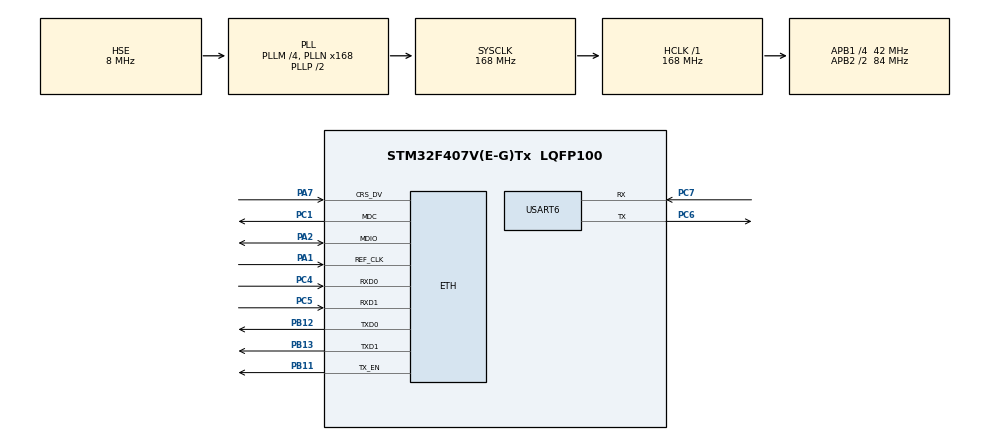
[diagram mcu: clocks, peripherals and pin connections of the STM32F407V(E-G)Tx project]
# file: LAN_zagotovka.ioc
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ETH.MediaInterface=ETH_MEDIA_INTERFACE_RMII
LWIP.API_LIB_DEBUG=LWIP_DBG_ON
LWIP.API_MSG_DEBUG=LWIP_DBG_ON
LWIP.AUTOIP_DEBUG=LWIP_DBG_ON
LWIP.DHCP6_DEBUG=LWIP_DBG_ON
LWIP.DHCP_DEBUG=LWIP_DBG_ON
LWIP.DNS_DEBUG=LWIP_DBG_ON
LWIP.ETHARP_DEBUG=LWIP_DBG_ON
LWIP.GATEWAY_ADDRESS=192.168.018.001
LWIP.HTTPD_DEBUG=LWIP_DBG_ON
LWIP.HTTPD_DEBUG_TIMING=LWIP_DBG_ON
LWIP.ICMP_DEBUG=LWIP_DBG_ON
LWIP.IGMP_DEBUG=LWIP_DBG_ON
LWIP.INET_DEBUG=LWIP_DBG_ON
LWIP.IP6_DEBUG=LWIP_DBG_ON
LWIP.IP_ADDRESS=192.168.018.111
LWIP.IP_DEBUG=LWIP_DBG_ON
LWIP.IP_REASS_DEBUG=LWIP_DBG_ON
LWIP.LWIP_DHCP=1
LWIP.LWIP_HTTPD=1
LWIP.LWIP_HTTPD_CGI=1
LWIP.LWIP_HTTPD_DYNAMIC_HEADERS=1
LWIP.LWIP_HTTPD_MAX_REQUEST_URI_LEN=1000
LWIP.LWIP_HTTPD_MAX_REQ_LENGTH=1500
LWIP.LWIP_HTTPD_MAX_TAG_INSERT_LEN=800
LWIP.LWIP_HTTPD_SSI=1
LWIP.LWIP_HTTPD_SSI_INCLUDE_TAG=0
LWIP.LWIP_HTTPD_SSI_MULTIPART=1
LWIP.LWIP_HTTPD_SUPPORT_POST=1
LWIP.LWIP_NETIF_LINK_CALLBACK=1
LWIP.LWIP_TESTMODE=1
LWIP.MDNS_DEBUG=LWIP_DBG_ON
LWIP.MEMP_DEBUG=LWIP_DBG_ON
LWIP.MEMP_NUM_PBUF=16
LWIP.MEMP_NUM_SYS_TIMEOUT=5
LWIP.MEMP_NUM_TCP_PCB=10
LWIP.MEMP_NUM_TCP_SEG=16
LWIP.MEMP_NUM_UDP_PCB=10
LWIP.MEM_DEBUG=LWIP_DBG_ON
LWIP.NETIF_DEBUG=LWIP_DBG_ON
LWIP.NETMASK_ADDRESS=255.255.255.000
LWIP.PBUF_DEBUG=LWIP_DBG_ON
LWIP.PBUF_POOL_SIZE=16
LWIP.PPP_DEBUG=LWIP_DBG_ON
LWIP.RAW_DEBUG=LWIP_DBG_ON
LWIP.SLIP_DEBUG=LWIP_DBG_ON
LWIP.SMTP_DEBUG=LWIP_DBG_ON
LWIP.SNMP_DEBUG=LWIP_DBG_ON
LWIP.SNMP_MIB_DEBUG=LWIP_DBG_ON
LWIP.SNTP_DEBUG=LWIP_DBG_ON
LWIP.SOCKETS_DEBUG=LWIP_DBG_ON
LWIP.SYS_DEBUG=LWIP_DBG_ON
LWIP.TCPIP_DEBUG=LWIP_DBG_ON
LWIP.TCP_CWND_DEBUG=LWIP_DBG_ON
LWIP.TCP_DEBUG=LWIP_DBG_ON
LWIP.TCP_FR_DEBUG=LWIP_DBG_ON
LWIP.TCP_INPUT_DEBUG=LWIP_DBG_ON
LWIP.TCP_OUTPUT_DEBUG=LWIP_DBG_ON
LWIP.TCP_QLEN_DEBUG=LWIP_DBG_ON
LWIP.TCP_RST_DEBUG=LWIP_DBG_ON
LWIP.TCP_RTO_DEBUG=LWIP_DBG_ON
LWIP.TCP_WND_DEBUG=LWIP_DBG_ON
LWIP.TFTP_DEBUG=LWIP_DBG_ON
LWIP.TIMERS_DEBUG=LWIP_DBG_ON
LWIP.UDP_DEBUG=LWIP_DBG_ON
LWIP.Version=v2.1.2_Cube
Mcu.Family=STM32F4
Mcu.Name=STM32F407V(E-G)Tx
Mcu.Package=LQFP100
NVIC.PriorityGroup=NVIC_PRIORITYGROUP_4
NVIC.TIM8_TRG_COM_TIM14_IRQn=true\:15\:0\:false\:false\:true\:false\:true
NVIC.TimeBase=TIM8_TRG_COM_TIM14_IRQn
NVIC.TimeBaseIP=TIM14
PA1.Mode=RMII
PA1.Signal=ETH_REF_CLK
PA13.Mode=Serial_Wire
PA13.Signal=SYS_JTMS-SWDIO
PA14.Mode=Serial_Wire
PA14.Signal=SYS_JTCK-SWCLK
PA2.Mode=RMII
PA2.Signal=ETH_MDIO
PA7.Mode=RMII
PA7.Signal=ETH_CRS_DV
PB11.Mode=RMII
PB11.Signal=ETH_TX_EN
PB12.Mode=RMII
PB12.Signal=ETH_TXD0
PB13.Mode=RMII
PB13.Signal=ETH_TXD1
PC1.Mode=RMII
PC1.Signal=ETH_MDC
PC4.Mode=RMII
PC4.Signal=ETH_RXD0
PC5.Mode=RMII
PC5.Signal=ETH_RXD1
PC6.Mode=Asynchronous
PC6.Signal=USART6_TX
PC7.Mode=Asynchronous
PC7.Signal=USART6_RX
PH0-OSC_IN.Mode=HSE-External-Oscillator
PH0-OSC_IN.Signal=RCC_OSC_IN
PH1-OSC_OUT.Mode=HSE-External-Oscillator
PH1-OSC_OUT.Signal=RCC_OSC_OUT
ProjectManager.HeapSize=0x200
ProjectManager.StackSize=0x400
ProjectManager.TargetToolchain=STM32CubeIDE
RCC.48MHZClocksFreq_Value=84000000
RCC.AHBFreq_Value=168000000
RCC.APB1CLKDivider=RCC_HCLK_DIV4
RCC.APB1Freq_Value=42000000
RCC.APB1TimFreq_Value=84000000
RCC.APB2CLKDivider=RCC_HCLK_DIV2
RCC.APB2Freq_Value=84000000
RCC.APB2TimFreq_Value=168000000
RCC.CortexFreq_Value=168000000
RCC.HCLKFreq_Value=168000000
RCC.HSE_VALUE=8000000
RCC.HSI_VALUE=16000000
RCC.LSE_VALUE=32768
RCC.PLLM=4
RCC.PLLN=168
RCC.PLLSourceVirtual=RCC_PLLSOURCE_HSE
RCC.SYSCLKFreq_VALUE=168000000
RCC.SYSCLKSource=RCC_SYSCLKSOURCE_PLLCLK
RCC.VCOOutputFreq_Value=336000000
USART6.VirtualMode=VM_ASYNC
VP_LWIP_VS_Enabled.Mode=Enabled
VP_SYS_VS_tim14.Mode=TIM14
board=custom

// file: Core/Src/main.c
/* USER CODE BEGIN Header */
/**
  ******************************************************************************
  * @file           : main.c
  * @brief          : Main program body
  ******************************************************************************
  * @attention
  *
  * Copyright (c) 2022 STMicroelectronics.
  * All rights reserved.
  *
  * This software is licensed under terms that can be found in the LICENSE file
  * in the root directory of this software component.
  * If no LICENSE file comes with this software, it is provided AS-IS.
  *
  ******************************************************************************
  */
/* USER CODE END Header */
#include "main.h"
#include "lwip.h"

/* USER CODE BEGIN Includes */
#include <stdio.h>/* для printf */
#include "lwip/apps/httpd.h" // including httpd.h [- HTTPd #1 -]
/* USER CODE END Includes */

UART_HandleTypeDef huart6;

void SystemClock_Config(void);
static void MX_GPIO_Init(void);
static void MX_USART6_UART_Init(void);
/* USER CODE BEGIN PFP */
int _write(int file, char *ptr, int len) {
	int i;
	HAL_UART_Transmit(&huart6, (uint8_t*) ptr, len, 50);
	for (i = 0; i < len; i++) {
		ITM_SendChar(*ptr++);
	}
	return len;
}
/* USER CODE END PFP */

/* USER CODE BEGIN 0 */
extern struct netif gnetif;
/* USER CODE END 0 */

int main(void)
{

  /* MCU Configuration--------------------------------------------------------*/

  /* Reset of all peripherals, Initializes the Flash interface and the Systick. */
  HAL_Init();

  /* Configure the system clock */
  SystemClock_Config();

  /* Initialize all configured peripherals */
  MX_GPIO_Init();
  MX_USART6_UART_Init();
  MX_LWIP_Init();
  /* USER CODE BEGIN 2 */
  http_server_init();
  /* USER CODE END 2 */

  /* Infinite loop */
  /* USER CODE BEGIN WHILE */
  printf("Hello world! \r\n");

  while (1)
  {
    /* USER CODE END WHILE */

    /* USER CODE BEGIN 3 */
	  ethernetif_input(&gnetif);
	  sys_check_timeouts();
  }
  /* USER CODE END 3 */
}

void SystemClock_Config(void)
{
  RCC_OscInitTypeDef RCC_OscInitStruct = {0};
  RCC_ClkInitTypeDef RCC_ClkInitStruct = {0};

  /** Configure the main internal regulator output voltage
  */
  __HAL_RCC_PWR_CLK_ENABLE();
  __HAL_PWR_VOLTAGESCALING_CONFIG(PWR_REGULATOR_VOLTAGE_SCALE1);
  /** Initializes the RCC Oscillators according to the specified parameters
  * in the RCC_OscInitTypeDef structure.
  */
  RCC_OscInitStruct.OscillatorType = RCC_OSCILLATORTYPE_HSE;
  RCC_OscInitStruct.HSEState = RCC_HSE_ON;
  RCC_OscInitStruct.PLL.PLLState = RCC_PLL_ON;
  RCC_OscInitStruct.PLL.PLLSource = RCC_PLLSOURCE_HSE;
  RCC_OscInitStruct.PLL.PLLM = 4;
  RCC_OscInitStruct.PLL.PLLN = 168;
  RCC_OscInitStruct.PLL.PLLP = RCC_PLLP_DIV2;
  RCC_OscInitStruct.PLL.PLLQ = 4;
  if (HAL_RCC_OscConfig(&RCC_OscInitStruct) != HAL_OK)
  {
    Error_Handler();
  }
  /** Initializes the CPU, AHB and APB buses clocks
  */
  RCC_ClkInitStruct.ClockType = RCC_CLOCKTYPE_HCLK|RCC_CLOCKTYPE_SYSCLK
                              |RCC_CLOCKTYPE_PCLK1|RCC_CLOCKTYPE_PCLK2;
  RCC_ClkInitStruct.SYSCLKSource = RCC_SYSCLKSOURCE_PLLCLK;
  RCC_ClkInitStruct.AHBCLKDivider = RCC_SYSCLK_DIV1;
  RCC_ClkInitStruct.APB1CLKDivider = RCC_HCLK_DIV4;
  RCC_ClkInitStruct.APB2CLKDivider = RCC_HCLK_DIV2;

  if (HAL_RCC_ClockConfig(&RCC_ClkInitStruct, FLASH_LATENCY_5) != HAL_OK)
  {
    Error_Handler();
  }
}

static void MX_USART6_UART_Init(void)
{

  huart6.Instance = USART6;
  huart6.Init.BaudRate = 115200;
  huart6.Init.WordLength = UART_WORDLENGTH_8B;
  huart6.Init.StopBits = UART_STOPBITS_1;
  huart6.Init.Parity = UART_PARITY_NONE;
  huart6.Init.Mode = UART_MODE_TX_RX;
  huart6.Init.HwFlowCtl = UART_HWCONTROL_NONE;
  huart6.Init.OverSampling = UART_OVERSAMPLING_16;
  if (HAL_UART_Init(&huart6) != HAL_OK)
  {
    Error_Handler();
  }

}

static void MX_GPIO_Init(void)
{

  /* GPIO Ports Clock Enable */
  __HAL_RCC_GPIOH_CLK_ENABLE();
  __HAL_RCC_GPIOC_CLK_ENABLE();
  __HAL_RCC_GPIOA_CLK_ENABLE();
  __HAL_RCC_GPIOB_CLK_ENABLE();

}

void HAL_TIM_PeriodElapsedCallback(TIM_HandleTypeDef *htim)
{
  if (htim->Instance == TIM14) {
    HAL_IncTick();
  }
}

void Error_Handler(void)
{
  __disable_irq();
  while (1)
  {
  }
}
